# STM32F407 register map
File version: 1.4
CPU: CM4 r0p1, little endian, MPU, FPU, 4 interrupt priority bits
Registers are 32-bit, read-write, reset 0x0 unless marked. A register's access mark holds for its fields unless they carry their own. Offsets are from the block's base; [hi:lo] are bit positions.

## Ethernet_MAC — Ethernet: media access control (MAC)
Base 0x40028000
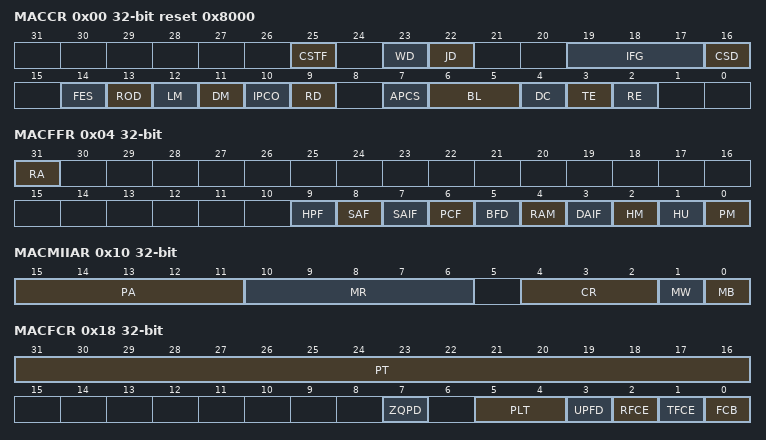
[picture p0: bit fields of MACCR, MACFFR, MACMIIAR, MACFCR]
0x00 MACCR reset 0x8000 — Ethernet MAC configuration register
  [25] CSTF, [23] WD, [22] JD, [19:17] IFG, [16] CSD, [14] FES, [13] ROD, [12] LM, [11] DM, [10] IPCO, [9] RD, [7] APCS, [6:5] BL, [4] DC, [3] TE, [2] RE
0x04 MACFFR — Ethernet MAC frame filter register
  [31] RA, [9] HPF, [8] SAF, [7] SAIF, [6] PCF, [5] BFD, [4] RAM, [3] DAIF, [2] HM, [1] HU, [0] PM
0x08 MACHTHR — Ethernet MAC hash table high register
  [31:0] HTH
0x0C MACHTLR — Ethernet MAC hash table low register
  [31:0] HTL
0x10 MACMIIAR — Ethernet MAC MII address register
  [15:11] PA, [10:6] MR, [4:2] CR, [1] MW, [0] MB
0x14 MACMIIDR — Ethernet MAC MII data register
  [15:0] TD
0x18 MACFCR — Ethernet MAC flow control register
  [31:16] PT, [7] ZQPD, [5:4] PLT, [3] UPFD, [2] RFCE, [1] TFCE, [0] FCB
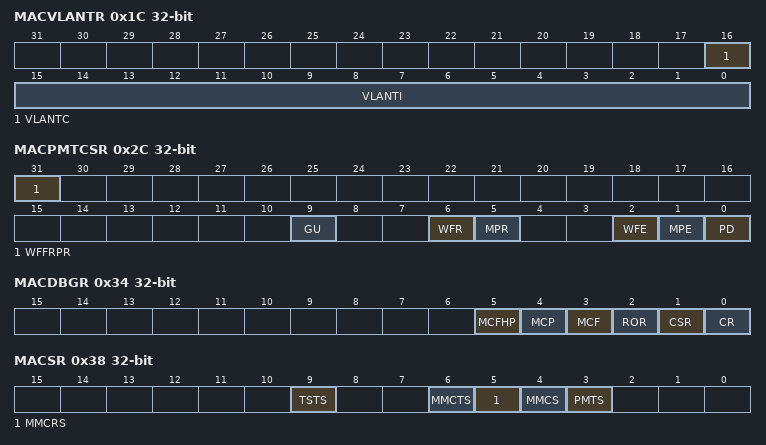
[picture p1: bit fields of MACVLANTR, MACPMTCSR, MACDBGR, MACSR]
0x1C MACVLANTR — Ethernet MAC VLAN tag register
  [16] VLANTC, [15:0] VLANTI
0x2C MACPMTCSR — Ethernet MAC PMT control and status register
  [31] WFFRPR, [9] GU, [6] WFR, [5] MPR, [2] WFE, [1] MPE, [0] PD
0x34 MACDBGR ro — Ethernet MAC debug register
  [5] MCFHP, [4] MCP, [3] MCF, [2] ROR, [1] CSR, [0] CR
0x38 MACSR access per field — Ethernet MAC interrupt status register
  [9] TSTS rw, [6] MMCTS ro, [5] MMCRS ro, [4] MMCS ro, [3] PMTS ro
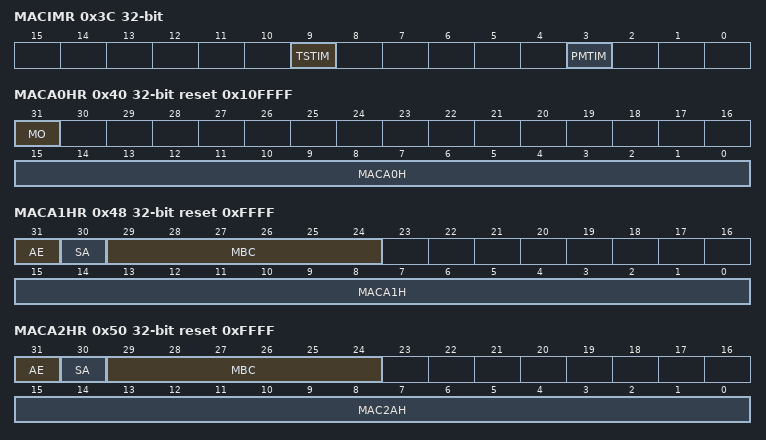
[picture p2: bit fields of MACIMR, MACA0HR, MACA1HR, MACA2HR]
0x3C MACIMR — Ethernet MAC interrupt mask register
  [9] TSTIM, [3] PMTIM
0x40 MACA0HR access per field reset 0x10FFFF — Ethernet MAC address 0 high register
  [31] MO ro — Always 1
  [15:0] MACA0H rw — MAC address0 high
0x44 MACA0LR reset 0xFFFFFFFF — Ethernet MAC address 0 low register
  [31:0] MACA0L — 0
0x48 MACA1HR reset 0xFFFF — Ethernet MAC address 1 high register
  [31] AE, [30] SA, [29:24] MBC, [15:0] MACA1H
0x4C MACA1LR reset 0xFFFFFFFF — Ethernet MAC address1 low register
0x50 MACA2HR reset 0xFFFF — Ethernet MAC address 2 high register
  [31] AE, [30] SA, [29:24] MBC, [15:0] MAC2AH
0x54 MACA2LR reset 0xFFFFFFFF — Ethernet MAC address 2 low register
  [30:0] MACA2L
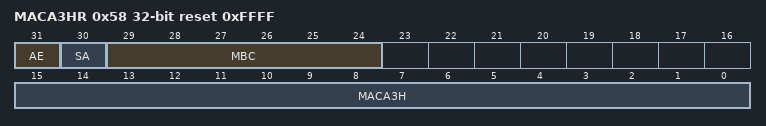
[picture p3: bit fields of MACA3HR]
0x58 MACA3HR reset 0xFFFF — Ethernet MAC address 3 high register
  [31] AE, [30] SA, [29:24] MBC, [15:0] MACA3H
0x5C MACA3LR reset 0xFFFFFFFF — Ethernet MAC address 3 low register
  [31:0] MBCA3L

## Ethernet_MMC — Ethernet: MAC management counters
Base 0x40028100
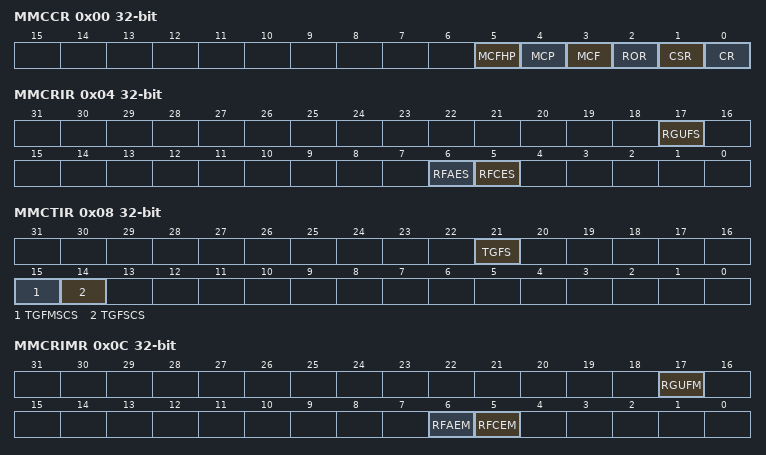
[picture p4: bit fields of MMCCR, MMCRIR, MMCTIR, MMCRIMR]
0x00 MMCCR — Ethernet MMC control register
  [5] MCFHP, [4] MCP, [3] MCF, [2] ROR, [1] CSR, [0] CR
0x04 MMCRIR — Ethernet MMC receive interrupt register
  [17] RGUFS, [6] RFAES, [5] RFCES
0x08 MMCTIR ro — Ethernet MMC transmit interrupt register
  [21] TGFS, [15] TGFMSCS, [14] TGFSCS
0x0C MMCRIMR — Ethernet MMC receive interrupt mask register
  [17] RGUFM, [6] RFAEM, [5] RFCEM
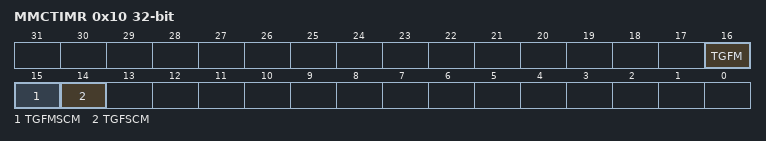
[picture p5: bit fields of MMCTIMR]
0x10 MMCTIMR — Ethernet MMC transmit interrupt mask register
  [16] TGFM, [15] TGFMSCM, [14] TGFSCM
0x4C MMCTGFSCCR ro — Ethernet MMC transmitted good frames after a single collision counter
  [31:0] TGFSCC
0x50 MMCTGFMSCCR ro — Ethernet MMC transmitted good frames after more than a single collision
  [31:0] TGFMSCC
0x68 MMCTGFCR ro — Ethernet MMC transmitted good frames counter register
  [31:0] TGFC — HTL
0x94 MMCRFCECR ro — Ethernet MMC received frames with CRC error counter register
  [31:0] RFCFC
0x98 MMCRFAECR ro — Ethernet MMC received frames with alignment error counter register
  [31:0] RFAEC
0xC4 MMCRGUFCR ro — MMC received good unicast frames counter register
  [31:0] RGUFC

## Ethernet_PTP — Ethernet: Precision time protocol
Base 0x40028700
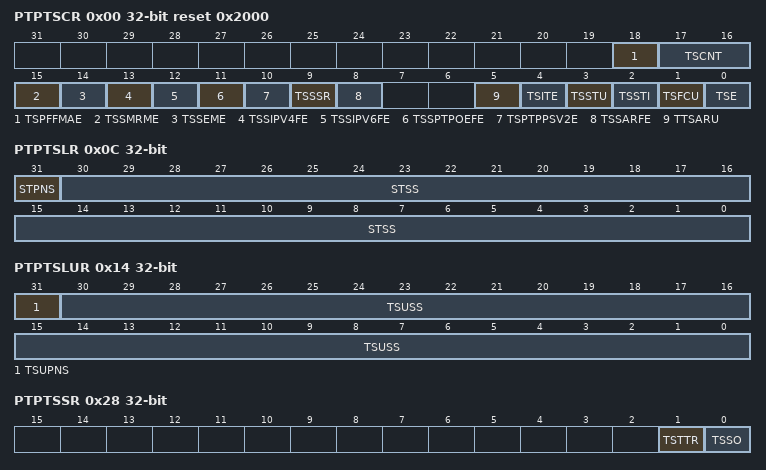
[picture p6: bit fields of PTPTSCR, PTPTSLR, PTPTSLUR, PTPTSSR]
0x00 PTPTSCR reset 0x2000 — Ethernet PTP time stamp control register
  [18] TSPFFMAE, [17:16] TSCNT, [15] TSSMRME, [14] TSSEME, [13] TSSIPV4FE, [12] TSSIPV6FE, [11] TSSPTPOEFE, [10] TSPTPPSV2E, [9] TSSSR, [8] TSSARFE, [5] TTSARU, [4] TSITE, [3] TSSTU, [2] TSSTI, [1] TSFCU, [0] TSE
0x04 PTPSSIR — Ethernet PTP subsecond increment register
  [7:0] STSSI
0x08 PTPTSHR ro — Ethernet PTP time stamp high register
  [31:0] STS
0x0C PTPTSLR ro — Ethernet PTP time stamp low register
  [31] STPNS, [30:0] STSS
0x10 PTPTSHUR — Ethernet PTP time stamp high update register
  [31:0] TSUS
0x14 PTPTSLUR — Ethernet PTP time stamp low update register
  [31] TSUPNS, [30:0] TSUSS
0x18 PTPTSAR — Ethernet PTP time stamp addend register
  [31:0] TSA
0x1C PTPTTHR — Ethernet PTP target time high register
  [31:0] TTSH — 0
0x20 PTPTTLR — Ethernet PTP target time low register
  [31:0] TTSL
0x28 PTPTSSR ro — Ethernet PTP time stamp status register
  [1] TSTTR, [0] TSSO
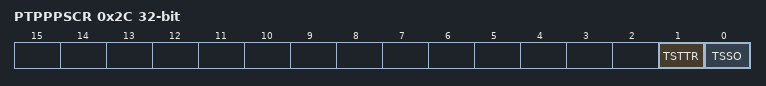
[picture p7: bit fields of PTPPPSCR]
0x2C PTPPPSCR ro — Ethernet PTP PPS control register
  [1] TSTTR, [0] TSSO
